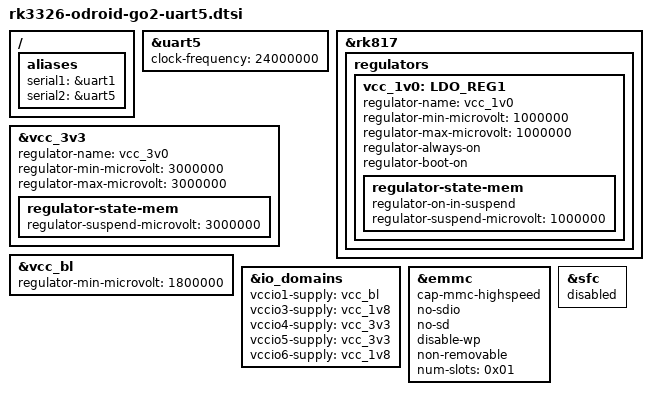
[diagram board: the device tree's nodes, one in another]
/ {
	aliases {
		serial1 = &uart1;
		serial2 = &uart5;
	};
};

&uart5 {
	clock-frequency = <24000000>;
	bootph-all;
	status = "okay";
};

&rk817 {
	regulators {
		vcc_1v0: LDO_REG1 {
			regulator-name = "vcc_1v0";
			regulator-min-microvolt = <1000000>;
			regulator-max-microvolt = <1000000>;
			regulator-always-on;
			regulator-boot-on;

			regulator-state-mem {
				regulator-on-in-suspend;
				regulator-suspend-microvolt = <1000000>;
			};
		};
	};
};

&vcc_3v3 {
	regulator-name = "vcc_3v0";
	regulator-min-microvolt = <3000000>;
	regulator-max-microvolt = <3000000>;

	regulator-state-mem {
		regulator-suspend-microvolt = <3000000>;
	};
};

&vcc_bl {
	regulator-min-microvolt = <1800000>;
};

&io_domains {
	vccio1-supply = <&vcc_bl>;
	vccio3-supply = <&vcc_1v8>;
	vccio4-supply = <&vcc_3v3>;
	vccio5-supply = <&vcc_3v3>;
	vccio6-supply = <&vcc_1v8>;
};

&emmc {
	cap-mmc-highspeed;
	no-sdio;
	no-sd;
	disable-wp;
	non-removable;
	num-slots = <0x01>;
};

&sfc {
	status = "disabled";
};
